# ECC_AGGR1_ECC_AGGR register map
Vendor: Texas Instruments
Registers are 32-bit, access not given, reset 0x0 unless marked. A register's access mark holds for its fields unless they carry their own. Offsets are as the file gives them; [hi:lo] are bit positions; {n}, {i} and the like mark numbered series.

## ECC_AGGR1_ECC_AGGR (part 6 of 6)
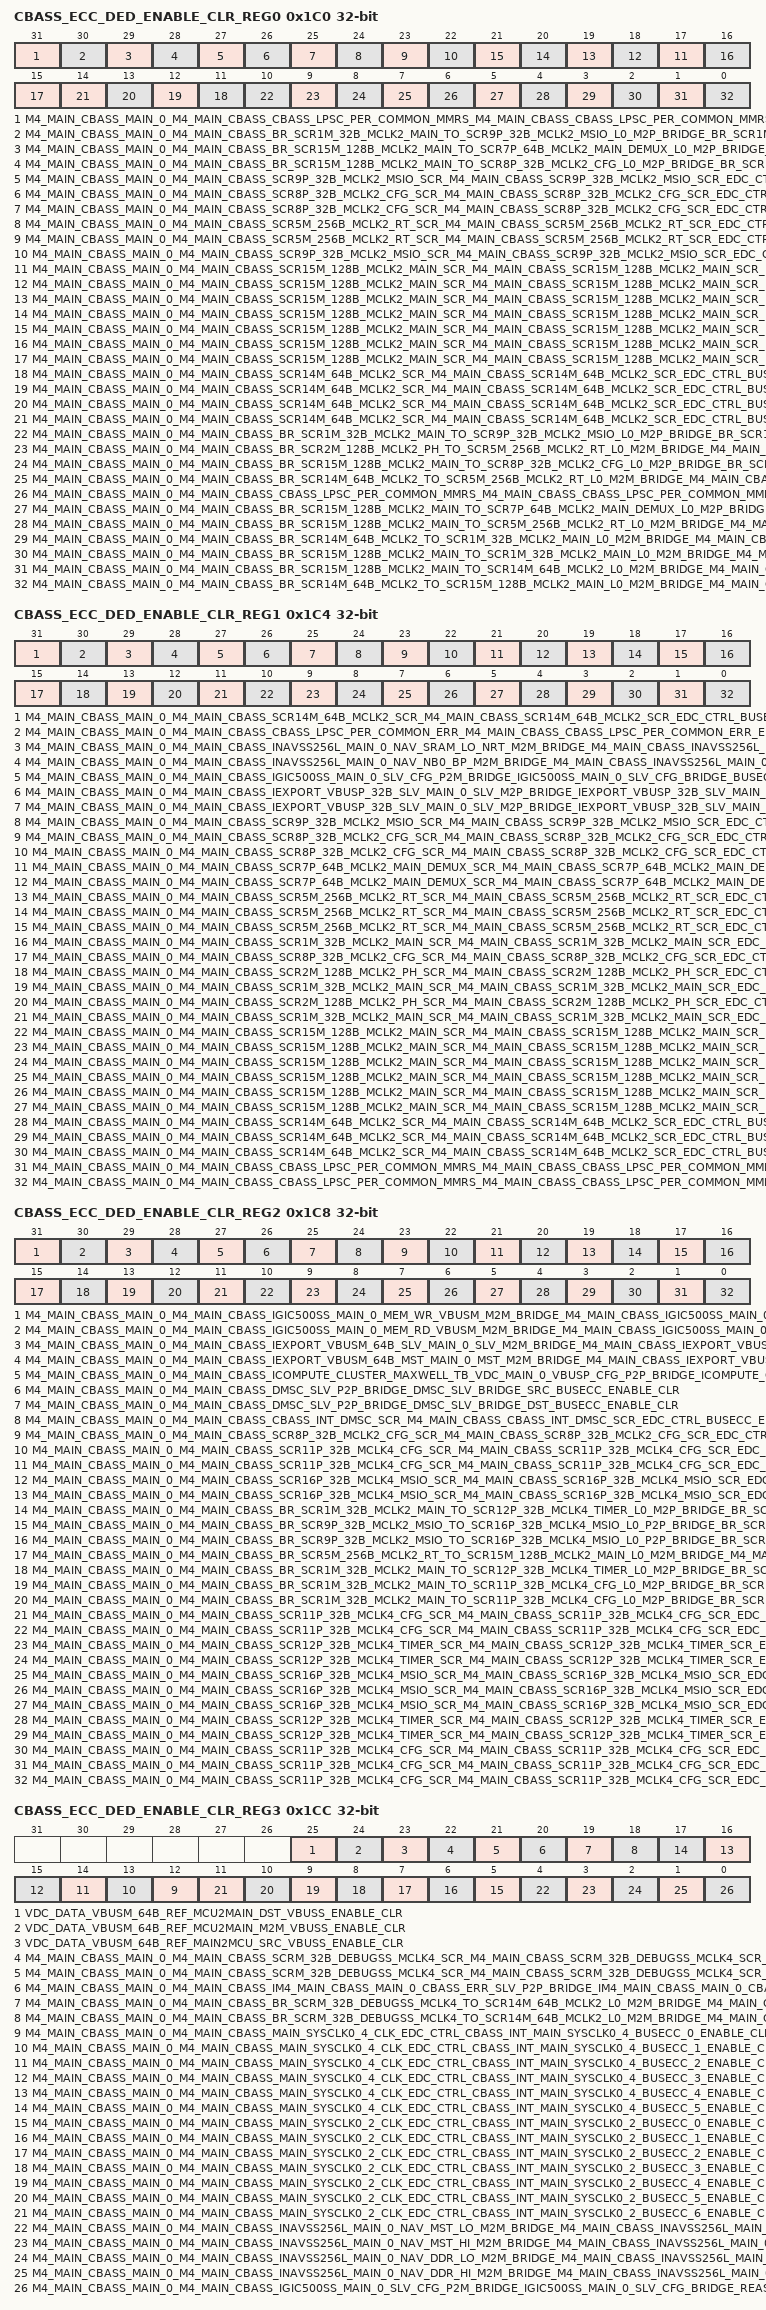
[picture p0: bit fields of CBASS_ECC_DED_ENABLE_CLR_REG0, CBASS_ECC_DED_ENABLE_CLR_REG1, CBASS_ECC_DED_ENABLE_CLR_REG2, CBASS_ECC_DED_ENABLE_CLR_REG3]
0x1C0 CBASS_ECC_DED_ENABLE_CLR_REG0 — Return to the . Interrupt Enable Clear Register 0
  [31] M4_MAIN_CBASS_MAIN_0_M4_MAIN_CBASS_CBASS_LPSC_PER_COMMON_MMRS_M4_MAIN_CBASS_CBASS_LPSC_PER_COMMON_MMRS_EDC_CTRL_BUSECC_1_ENABLE_CLR — Interrupt Enable Clear Register for m4_main_cbass_main_0_m4_main_cbass_cbass_LPSC_per_common_mmrs_m4_main_cbass_cbass_LPSC_per_common_mmrs_edc_ctrl_busecc_1__pend (access RW1C)
  [30] M4_MAIN_CBASS_MAIN_0_M4_MAIN_CBASS_BR_SCR1M_32B_MCLK2_MAIN_TO_SCR9P_32B_MCLK2_MSIO_L0_M2P_BRIDGE_BR_SCR1M_32B_MCLK2_MAIN_TO_SCR9P_32B_MCLK2_MSIO_L0_BRIDGE_DST_BUSECC_ENABLE_CLR — Interrupt Enable Clear Register for m4_main_cbass_main_0_m4_main_cbass_br_SCR1M_32b_MCLK2_main_to_SCR9P_32b_MCLK2_MSIO_l0_m2p_bridge_br_SCR1M_32b_MCLK2_main_to_SCR9P_32b_MCLK2_MSIO_l0_bridge_dst_busecc__pend (access RW1C)
  [29] M4_MAIN_CBASS_MAIN_0_M4_MAIN_CBASS_BR_SCR15M_128B_MCLK2_MAIN_TO_SCR7P_64B_MCLK2_MAIN_DEMUX_L0_M2P_BRIDGE_BR_SCR15M_128B_MCLK2_MAIN_TO_SCR7P_64B_MCLK2_MAIN_DEMUX_L0_BRIDGE_SRC_BUSECC_ENABLE_CLR — Interrupt Enable Clear Register for m4_main_cbass_main_0_m4_main_cbass_br_SCR15M_128b_MCLK2_main_to_SCR7P_64b_MCLK2_main_demux_l0_m2p_bridge_br_SCR15M_128b_MCLK2_main_to_SCR7P_64b_MCLK2_main_demux_l0_bridge_src_busecc__pend (access RW1C)
  [28] M4_MAIN_CBASS_MAIN_0_M4_MAIN_CBASS_BR_SCR15M_128B_MCLK2_MAIN_TO_SCR8P_32B_MCLK2_CFG_L0_M2P_BRIDGE_BR_SCR15M_128B_MCLK2_MAIN_TO_SCR8P_32B_MCLK2_CFG_L0_BRIDGE_DST_BUSECC_ENABLE_CLR — Interrupt Enable Clear Register for m4_main_cbass_main_0_m4_main_cbass_br_SCR15M_128b_MCLK2_main_to_SCR8P_32b_MCLK2_CFG_l0_m2p_bridge_br_SCR15M_128b_MCLK2_main_to_SCR8P_32b_MCLK2_CFG_l0_bridge_dst_busecc__pend (access RW1C)
  [27] M4_MAIN_CBASS_MAIN_0_M4_MAIN_CBASS_SCR9P_32B_MCLK2_MSIO_SCR_M4_MAIN_CBASS_SCR9P_32B_MCLK2_MSIO_SCR_EDC_CTRL_BUSECC_0_ENABLE_CLR — Interrupt Enable Clear Register for m4_main_cbass_main_0_m4_main_cbass_SCR9P_32b_MCLK2_MSIO_scr_m4_main_cbass_SCR9P_32b_MCLK2_MSIO_scr_edc_ctrl_busecc_0__pend (access RW1C)
  [26] M4_MAIN_CBASS_MAIN_0_M4_MAIN_CBASS_SCR8P_32B_MCLK2_CFG_SCR_M4_MAIN_CBASS_SCR8P_32B_MCLK2_CFG_SCR_EDC_CTRL_BUSECC_0_ENABLE_CLR — Interrupt Enable Clear Register for m4_main_cbass_main_0_m4_main_cbass_SCR8P_32b_MCLK2_CFG_scr_m4_main_cbass_SCR8P_32b_MCLK2_CFG_scr_edc_ctrl_busecc_0__pend (access RW1C)
  [25] M4_MAIN_CBASS_MAIN_0_M4_MAIN_CBASS_SCR8P_32B_MCLK2_CFG_SCR_M4_MAIN_CBASS_SCR8P_32B_MCLK2_CFG_SCR_EDC_CTRL_BUSECC_2_ENABLE_CLR — Interrupt Enable Clear Register for m4_main_cbass_main_0_m4_main_cbass_SCR8P_32b_MCLK2_CFG_scr_m4_main_cbass_SCR8P_32b_MCLK2_CFG_scr_edc_ctrl_busecc_2__pend (access RW1C)
  [24] M4_MAIN_CBASS_MAIN_0_M4_MAIN_CBASS_SCR5M_256B_MCLK2_RT_SCR_M4_MAIN_CBASS_SCR5M_256B_MCLK2_RT_SCR_EDC_CTRL_BUSECC_1_ENABLE_CLR — Interrupt Enable Clear Register for m4_main_cbass_main_0_m4_main_cbass_SCR5M_256b_MCLK2_RT_scr_m4_main_cbass_SCR5M_256b_MCLK2_RT_scr_edc_ctrl_busecc_1__pend (access RW1C)
  [23] M4_MAIN_CBASS_MAIN_0_M4_MAIN_CBASS_SCR5M_256B_MCLK2_RT_SCR_M4_MAIN_CBASS_SCR5M_256B_MCLK2_RT_SCR_EDC_CTRL_BUSECC_0_ENABLE_CLR — Interrupt Enable Clear Register for m4_main_cbass_main_0_m4_main_cbass_SCR5M_256b_MCLK2_RT_scr_m4_main_cbass_SCR5M_256b_MCLK2_RT_scr_edc_ctrl_busecc_0__pend (access RW1C)
  [22] M4_MAIN_CBASS_MAIN_0_M4_MAIN_CBASS_SCR9P_32B_MCLK2_MSIO_SCR_M4_MAIN_CBASS_SCR9P_32B_MCLK2_MSIO_SCR_EDC_CTRL_BUSECC_1_ENABLE_CLR — Interrupt Enable Clear Register for m4_main_cbass_main_0_m4_main_cbass_SCR9P_32b_MCLK2_MSIO_scr_m4_main_cbass_SCR9P_32b_MCLK2_MSIO_scr_edc_ctrl_busecc_1__pend (access RW1C)
  [n+15] M4_MAIN_CBASS_MAIN_0_M4_MAIN_CBASS_SCR15M_128B_MCLK2_MAIN_SCR_M4_MAIN_CBASS_SCR15M_128B_MCLK2_MAIN_SCR_EDC_CTRL_BUSECC_{n}_ENABLE_CLR (n=2..6) — Interrupt Enable Clear Register for m4_main_cbass_main_0_m4_main_cbass_SCR15M_128b_MCLK2_main_scr_m4_main_cbass_SCR15M_128b_MCLK2_main_scr_edc_ctrl_busecc_{n}__pend (access RW1C)
  [16] M4_MAIN_CBASS_MAIN_0_M4_MAIN_CBASS_SCR15M_128B_MCLK2_MAIN_SCR_M4_MAIN_CBASS_SCR15M_128B_MCLK2_MAIN_SCR_EDC_CTRL_BUSECC_0_ENABLE_CLR — Interrupt Enable Clear Register for m4_main_cbass_main_0_m4_main_cbass_SCR15M_128b_MCLK2_main_scr_m4_main_cbass_SCR15M_128b_MCLK2_main_scr_edc_ctrl_busecc_0__pend (access RW1C)
  [15] M4_MAIN_CBASS_MAIN_0_M4_MAIN_CBASS_SCR15M_128B_MCLK2_MAIN_SCR_M4_MAIN_CBASS_SCR15M_128B_MCLK2_MAIN_SCR_EDC_CTRL_BUSECC_1_ENABLE_CLR — Interrupt Enable Clear Register for m4_main_cbass_main_0_m4_main_cbass_SCR15M_128b_MCLK2_main_scr_m4_main_cbass_SCR15M_128b_MCLK2_main_scr_edc_ctrl_busecc_1__pend (access RW1C)
  [n+11] M4_MAIN_CBASS_MAIN_0_M4_MAIN_CBASS_SCR14M_64B_MCLK2_SCR_M4_MAIN_CBASS_SCR14M_64B_MCLK2_SCR_EDC_CTRL_BUSECC_{n}_ENABLE_CLR (n=0..3) — Interrupt Enable Clear Register for m4_main_cbass_main_0_m4_main_cbass_SCR14M_64b_MCLK2_scr_m4_main_cbass_SCR14M_64b_MCLK2_scr_edc_ctrl_busecc_{n}__pend (access RW1C)
  [10] M4_MAIN_CBASS_MAIN_0_M4_MAIN_CBASS_BR_SCR1M_32B_MCLK2_MAIN_TO_SCR9P_32B_MCLK2_MSIO_L0_M2P_BRIDGE_BR_SCR1M_32B_MCLK2_MAIN_TO_SCR9P_32B_MCLK2_MSIO_L0_BRIDGE_SRC_BUSECC_ENABLE_CLR — Interrupt Enable Clear Register for m4_main_cbass_main_0_m4_main_cbass_br_SCR1M_32b_MCLK2_main_to_SCR9P_32b_MCLK2_MSIO_l0_m2p_bridge_br_SCR1M_32b_MCLK2_main_to_SCR9P_32b_MCLK2_MSIO_l0_bridge_src_busecc__pend (access RW1C)
  [9] M4_MAIN_CBASS_MAIN_0_M4_MAIN_CBASS_BR_SCR2M_128B_MCLK2_PH_TO_SCR5M_256B_MCLK2_RT_L0_M2M_BRIDGE_M4_MAIN_CBASS_BR_SCR2M_128B_MCLK2_PH_TO_SCR5M_256B_MCLK2_RT_L0_M2M_BRIDGE_SRC_EDC_CTRL_BUSECC_ENABLE_CLR — Interrupt Enable Clear Register for m4_main_cbass_main_0_m4_main_cbass_br_SCR2M_128b_MCLK2_PH_to_SCR5M_256b_MCLK2_RT_l0_m2m_bridge_m4_main_cbass_br_SCR2M_128b_MCLK2_PH_to_SCR5M_256b_MCLK2_RT_l0_m2m_bridge_src_edc_ctrl_busecc__pend (access RW1C)
  [8] M4_MAIN_CBASS_MAIN_0_M4_MAIN_CBASS_BR_SCR15M_128B_MCLK2_MAIN_TO_SCR8P_32B_MCLK2_CFG_L0_M2P_BRIDGE_BR_SCR15M_128B_MCLK2_MAIN_TO_SCR8P_32B_MCLK2_CFG_L0_BRIDGE_SRC_BUSECC_ENABLE_CLR — Interrupt Enable Clear Register for m4_main_cbass_main_0_m4_main_cbass_br_SCR15M_128b_MCLK2_main_to_SCR8P_32b_MCLK2_CFG_l0_m2p_bridge_br_SCR15M_128b_MCLK2_main_to_SCR8P_32b_MCLK2_CFG_l0_bridge_src_busecc__pend (access RW1C)
  [7] M4_MAIN_CBASS_MAIN_0_M4_MAIN_CBASS_BR_SCR14M_64B_MCLK2_TO_SCR5M_256B_MCLK2_RT_L0_M2M_BRIDGE_M4_MAIN_CBASS_BR_SCR14M_64B_MCLK2_TO_SCR5M_256B_MCLK2_RT_L0_M2M_BRIDGE_SRC_EDC_CTRL_BUSECC_ENABLE_CLR — Interrupt Enable Clear Register for m4_main_cbass_main_0_m4_main_cbass_br_SCR14M_64b_MCLK2_to_SCR5M_256b_MCLK2_RT_l0_m2m_bridge_m4_main_cbass_br_SCR14M_64b_MCLK2_to_SCR5M_256b_MCLK2_RT_l0_m2m_bridge_src_edc_ctrl_busecc__pend (access RW1C)
  [6] M4_MAIN_CBASS_MAIN_0_M4_MAIN_CBASS_CBASS_LPSC_PER_COMMON_MMRS_M4_MAIN_CBASS_CBASS_LPSC_PER_COMMON_MMRS_EDC_CTRL_BUSECC_0_ENABLE_CLR — Interrupt Enable Clear Register for m4_main_cbass_main_0_m4_main_cbass_cbass_LPSC_per_common_mmrs_m4_main_cbass_cbass_LPSC_per_common_mmrs_edc_ctrl_busecc_0__pend (access RW1C)
  [5] M4_MAIN_CBASS_MAIN_0_M4_MAIN_CBASS_BR_SCR15M_128B_MCLK2_MAIN_TO_SCR7P_64B_MCLK2_MAIN_DEMUX_L0_M2P_BRIDGE_BR_SCR15M_128B_MCLK2_MAIN_TO_SCR7P_64B_MCLK2_MAIN_DEMUX_L0_BRIDGE_DST_BUSECC_ENABLE_CLR — Interrupt Enable Clear Register for m4_main_cbass_main_0_m4_main_cbass_br_SCR15M_128b_MCLK2_main_to_SCR7P_64b_MCLK2_main_demux_l0_m2p_bridge_br_SCR15M_128b_MCLK2_main_to_SCR7P_64b_MCLK2_main_demux_l0_bridge_dst_busecc__pend (access RW1C)
  [4] M4_MAIN_CBASS_MAIN_0_M4_MAIN_CBASS_BR_SCR15M_128B_MCLK2_MAIN_TO_SCR5M_256B_MCLK2_RT_L0_M2M_BRIDGE_M4_MAIN_CBASS_BR_SCR15M_128B_MCLK2_MAIN_TO_SCR5M_256B_MCLK2_RT_L0_M2M_BRIDGE_SRC_EDC_CTRL_BUSECC_ENABLE_CLR — Interrupt Enable Clear Register for m4_main_cbass_main_0_m4_main_cbass_br_SCR15M_128b_MCLK2_main_to_SCR5M_256b_MCLK2_RT_l0_m2m_bridge_m4_main_cbass_br_SCR15M_128b_MCLK2_main_to_SCR5M_256b_MCLK2_RT_l0_m2m_bridge_src_edc_ctrl_busecc__pend (access RW1C)
  [3] M4_MAIN_CBASS_MAIN_0_M4_MAIN_CBASS_BR_SCR14M_64B_MCLK2_TO_SCR1M_32B_MCLK2_MAIN_L0_M2M_BRIDGE_M4_MAIN_CBASS_BR_SCR14M_64B_MCLK2_TO_SCR1M_32B_MCLK2_MAIN_L0_M2M_BRIDGE_SRC_EDC_CTRL_BUSECC_ENABLE_CLR — Interrupt Enable Clear Register for m4_main_cbass_main_0_m4_main_cbass_br_SCR14M_64b_MCLK2_to_SCR1M_32b_MCLK2_main_l0_m2m_bridge_m4_main_cbass_br_SCR14M_64b_MCLK2_to_SCR1M_32b_MCLK2_main_l0_m2m_bridge_src_edc_ctrl_busecc__pend (access RW1C)
  [2] M4_MAIN_CBASS_MAIN_0_M4_MAIN_CBASS_BR_SCR15M_128B_MCLK2_MAIN_TO_SCR1M_32B_MCLK2_MAIN_L0_M2M_BRIDGE_M4_MAIN_CBASS_BR_SCR15M_128B_MCLK2_MAIN_TO_SCR1M_32B_MCLK2_MAIN_L0_M2M_BRIDGE_SRC_EDC_CTRL_BUSECC_ENABLE_CLR — Interrupt Enable Clear Register for m4_main_cbass_main_0_m4_main_cbass_br_SCR15M_128b_MCLK2_main_to_SCR1M_32b_MCLK2_main_l0_m2m_bridge_m4_main_cbass_br_SCR15M_128b_MCLK2_main_to_SCR1M_32b_MCLK2_main_l0_m2m_bridge_src_edc_ctrl_busecc__pend (access RW1C)
  [1] M4_MAIN_CBASS_MAIN_0_M4_MAIN_CBASS_BR_SCR15M_128B_MCLK2_MAIN_TO_SCR14M_64B_MCLK2_L0_M2M_BRIDGE_M4_MAIN_CBASS_BR_SCR15M_128B_MCLK2_MAIN_TO_SCR14M_64B_MCLK2_L0_M2M_BRIDGE_SRC_EDC_CTRL_BUSECC_ENABLE_CLR — Interrupt Enable Clear Register for m4_main_cbass_main_0_m4_main_cbass_br_SCR15M_128b_MCLK2_main_to_SCR14M_64b_MCLK2_l0_m2m_bridge_m4_main_cbass_br_SCR15M_128b_MCLK2_main_to_SCR14M_64b_MCLK2_l0_m2m_bridge_src_edc_ctrl_busecc__pend (access RW1C)
  [0] M4_MAIN_CBASS_MAIN_0_M4_MAIN_CBASS_BR_SCR14M_64B_MCLK2_TO_SCR15M_128B_MCLK2_MAIN_L0_M2M_BRIDGE_M4_MAIN_CBASS_BR_SCR14M_64B_MCLK2_TO_SCR15M_128B_MCLK2_MAIN_L0_M2M_BRIDGE_SRC_EDC_CTRL_BUSECC_ENABLE_CLR — Interrupt Enable Clear Register for m4_main_cbass_main_0_m4_main_cbass_br_SCR14M_64b_MCLK2_to_SCR15M_128b_MCLK2_main_l0_m2m_bridge_m4_main_cbass_br_SCR14M_64b_MCLK2_to_SCR15M_128b_MCLK2_main_l0_m2m_bridge_src_edc_ctrl_busecc__pend (access RW1C)
0x1C4 CBASS_ECC_DED_ENABLE_CLR_REG1 — Return to the . Interrupt Enable Clear Register 1
  [31] M4_MAIN_CBASS_MAIN_0_M4_MAIN_CBASS_SCR14M_64B_MCLK2_SCR_M4_MAIN_CBASS_SCR14M_64B_MCLK2_SCR_EDC_CTRL_BUSECC_4_ENABLE_CLR — Interrupt Enable Clear Register for m4_main_cbass_main_0_m4_main_cbass_SCR14M_64b_MCLK2_scr_m4_main_cbass_SCR14M_64b_MCLK2_scr_edc_ctrl_busecc_4__pend (access RW1C)
  [30] M4_MAIN_CBASS_MAIN_0_M4_MAIN_CBASS_CBASS_LPSC_PER_COMMON_ERR_M4_MAIN_CBASS_CBASS_LPSC_PER_COMMON_ERR_EDC_CTRL_BUSECC_ENABLE_CLR — Interrupt Enable Clear Register for m4_main_cbass_main_0_m4_main_cbass_cbass_LPSC_per_common_err_m4_main_cbass_cbass_LPSC_per_common_err_edc_ctrl_busecc__pend (access RW1C)
  [29] M4_MAIN_CBASS_MAIN_0_M4_MAIN_CBASS_INAVSS256L_MAIN_0_NAV_SRAM_LO_NRT_M2M_BRIDGE_M4_MAIN_CBASS_INAVSS256L_MAIN_0_NAV_SRAM_LO_NRT_M2M_BRIDGE_SRC_EDC_CTRL_BUSECC_ENABLE_CLR — Interrupt Enable Clear Register for m4_main_cbass_main_0_m4_main_cbass_Inavss256l_main_0_nav_sram_lo_nrt_m2m_bridge_m4_main_cbass_Inavss256l_main_0_nav_sram_lo_nrt_m2m_bridge_src_edc_ctrl_busecc__pend (access RW1C)
  [28] M4_MAIN_CBASS_MAIN_0_M4_MAIN_CBASS_INAVSS256L_MAIN_0_NAV_NB0_BP_M2M_BRIDGE_M4_MAIN_CBASS_INAVSS256L_MAIN_0_NAV_NB0_BP_M2M_BRIDGE_SRC_EDC_CTRL_BUSECC_ENABLE_CLR — Interrupt Enable Clear Register for m4_main_cbass_main_0_m4_main_cbass_Inavss256l_main_0_nav_nb0_bp_m2m_bridge_m4_main_cbass_Inavss256l_main_0_nav_nb0_bp_m2m_bridge_src_edc_ctrl_busecc__pend (access RW1C)
  [27] M4_MAIN_CBASS_MAIN_0_M4_MAIN_CBASS_IGIC500SS_MAIN_0_SLV_CFG_P2M_BRIDGE_IGIC500SS_MAIN_0_SLV_CFG_BRIDGE_BUSECC_ENABLE_CLR — Interrupt Enable Clear Register for m4_main_cbass_main_0_m4_main_cbass_Igic500ss_main_0_slv_cfg_p2m_bridge_Igic500ss_main_0_slv_cfg_bridge_busecc__pend (access RW1C)
  [26] M4_MAIN_CBASS_MAIN_0_M4_MAIN_CBASS_IEXPORT_VBUSP_32B_SLV_MAIN_0_SLV_M2P_BRIDGE_IEXPORT_VBUSP_32B_SLV_MAIN_0_SLV_BRIDGE_SRC_BUSECC_ENABLE_CLR — Interrupt Enable Clear Register for m4_main_cbass_main_0_m4_main_cbass_Iexport_vbusp_32b_slv_main_0_slv_m2p_bridge_Iexport_vbusp_32b_slv_main_0_slv_bridge_src_busecc__pend (access RW1C)
  [25] M4_MAIN_CBASS_MAIN_0_M4_MAIN_CBASS_IEXPORT_VBUSP_32B_SLV_MAIN_0_SLV_M2P_BRIDGE_IEXPORT_VBUSP_32B_SLV_MAIN_0_SLV_BRIDGE_DST_BUSECC_ENABLE_CLR — Interrupt Enable Clear Register for m4_main_cbass_main_0_m4_main_cbass_Iexport_vbusp_32b_slv_main_0_slv_m2p_bridge_Iexport_vbusp_32b_slv_main_0_slv_bridge_dst_busecc__pend (access RW1C)
  [24] M4_MAIN_CBASS_MAIN_0_M4_MAIN_CBASS_SCR9P_32B_MCLK2_MSIO_SCR_M4_MAIN_CBASS_SCR9P_32B_MCLK2_MSIO_SCR_EDC_CTRL_BUSECC_2_ENABLE_CLR — Interrupt Enable Clear Register for m4_main_cbass_main_0_m4_main_cbass_SCR9P_32b_MCLK2_MSIO_scr_m4_main_cbass_SCR9P_32b_MCLK2_MSIO_scr_edc_ctrl_busecc_2__pend (access RW1C)
  [23] M4_MAIN_CBASS_MAIN_0_M4_MAIN_CBASS_SCR8P_32B_MCLK2_CFG_SCR_M4_MAIN_CBASS_SCR8P_32B_MCLK2_CFG_SCR_EDC_CTRL_BUSECC_4_ENABLE_CLR — Interrupt Enable Clear Register for m4_main_cbass_main_0_m4_main_cbass_SCR8P_32b_MCLK2_CFG_scr_m4_main_cbass_SCR8P_32b_MCLK2_CFG_scr_edc_ctrl_busecc_4__pend (access RW1C)
  [22] M4_MAIN_CBASS_MAIN_0_M4_MAIN_CBASS_SCR8P_32B_MCLK2_CFG_SCR_M4_MAIN_CBASS_SCR8P_32B_MCLK2_CFG_SCR_EDC_CTRL_BUSECC_3_ENABLE_CLR — Interrupt Enable Clear Register for m4_main_cbass_main_0_m4_main_cbass_SCR8P_32b_MCLK2_CFG_scr_m4_main_cbass_SCR8P_32b_MCLK2_CFG_scr_edc_ctrl_busecc_3__pend (access RW1C)
  [21] M4_MAIN_CBASS_MAIN_0_M4_MAIN_CBASS_SCR7P_64B_MCLK2_MAIN_DEMUX_SCR_M4_MAIN_CBASS_SCR7P_64B_MCLK2_MAIN_DEMUX_SCR_EDC_CTRL_BUSECC_1_ENABLE_CLR — Interrupt Enable Clear Register for m4_main_cbass_main_0_m4_main_cbass_SCR7P_64b_MCLK2_main_demux_scr_m4_main_cbass_SCR7P_64b_MCLK2_main_demux_scr_edc_ctrl_busecc_1__pend (access RW1C)
  [20] M4_MAIN_CBASS_MAIN_0_M4_MAIN_CBASS_SCR7P_64B_MCLK2_MAIN_DEMUX_SCR_M4_MAIN_CBASS_SCR7P_64B_MCLK2_MAIN_DEMUX_SCR_EDC_CTRL_BUSECC_0_ENABLE_CLR — Interrupt Enable Clear Register for m4_main_cbass_main_0_m4_main_cbass_SCR7P_64b_MCLK2_main_demux_scr_m4_main_cbass_SCR7P_64b_MCLK2_main_demux_scr_edc_ctrl_busecc_0__pend (access RW1C)
  [19] M4_MAIN_CBASS_MAIN_0_M4_MAIN_CBASS_SCR5M_256B_MCLK2_RT_SCR_M4_MAIN_CBASS_SCR5M_256B_MCLK2_RT_SCR_EDC_CTRL_BUSECC_4_ENABLE_CLR — Interrupt Enable Clear Register for m4_main_cbass_main_0_m4_main_cbass_SCR5M_256b_MCLK2_RT_scr_m4_main_cbass_SCR5M_256b_MCLK2_RT_scr_edc_ctrl_busecc_4__pend (access RW1C)
  [18] M4_MAIN_CBASS_MAIN_0_M4_MAIN_CBASS_SCR5M_256B_MCLK2_RT_SCR_M4_MAIN_CBASS_SCR5M_256B_MCLK2_RT_SCR_EDC_CTRL_BUSECC_3_ENABLE_CLR — Interrupt Enable Clear Register for m4_main_cbass_main_0_m4_main_cbass_SCR5M_256b_MCLK2_RT_scr_m4_main_cbass_SCR5M_256b_MCLK2_RT_scr_edc_ctrl_busecc_3__pend (access RW1C)
  [17] M4_MAIN_CBASS_MAIN_0_M4_MAIN_CBASS_SCR5M_256B_MCLK2_RT_SCR_M4_MAIN_CBASS_SCR5M_256B_MCLK2_RT_SCR_EDC_CTRL_BUSECC_2_ENABLE_CLR — Interrupt Enable Clear Register for m4_main_cbass_main_0_m4_main_cbass_SCR5M_256b_MCLK2_RT_scr_m4_main_cbass_SCR5M_256b_MCLK2_RT_scr_edc_ctrl_busecc_2__pend (access RW1C)
  [16] M4_MAIN_CBASS_MAIN_0_M4_MAIN_CBASS_SCR1M_32B_MCLK2_MAIN_SCR_M4_MAIN_CBASS_SCR1M_32B_MCLK2_MAIN_SCR_EDC_CTRL_BUSECC_1_ENABLE_CLR — Interrupt Enable Clear Register for m4_main_cbass_main_0_m4_main_cbass_SCR1M_32b_MCLK2_main_scr_m4_main_cbass_SCR1M_32b_MCLK2_main_scr_edc_ctrl_busecc_1__pend (access RW1C)
  [15] M4_MAIN_CBASS_MAIN_0_M4_MAIN_CBASS_SCR8P_32B_MCLK2_CFG_SCR_M4_MAIN_CBASS_SCR8P_32B_MCLK2_CFG_SCR_EDC_CTRL_BUSECC_1_ENABLE_CLR — Interrupt Enable Clear Register for m4_main_cbass_main_0_m4_main_cbass_SCR8P_32b_MCLK2_CFG_scr_m4_main_cbass_SCR8P_32b_MCLK2_CFG_scr_edc_ctrl_busecc_1__pend (access RW1C)
  [14] M4_MAIN_CBASS_MAIN_0_M4_MAIN_CBASS_SCR2M_128B_MCLK2_PH_SCR_M4_MAIN_CBASS_SCR2M_128B_MCLK2_PH_SCR_EDC_CTRL_BUSECC_1_ENABLE_CLR — Interrupt Enable Clear Register for m4_main_cbass_main_0_m4_main_cbass_SCR2M_128b_MCLK2_PH_scr_m4_main_cbass_SCR2M_128b_MCLK2_PH_scr_edc_ctrl_busecc_1__pend (access RW1C)
  [13] M4_MAIN_CBASS_MAIN_0_M4_MAIN_CBASS_SCR1M_32B_MCLK2_MAIN_SCR_M4_MAIN_CBASS_SCR1M_32B_MCLK2_MAIN_SCR_EDC_CTRL_BUSECC_2_ENABLE_CLR — Interrupt Enable Clear Register for m4_main_cbass_main_0_m4_main_cbass_SCR1M_32b_MCLK2_main_scr_m4_main_cbass_SCR1M_32b_MCLK2_main_scr_edc_ctrl_busecc_2__pend (access RW1C)
  [12] M4_MAIN_CBASS_MAIN_0_M4_MAIN_CBASS_SCR2M_128B_MCLK2_PH_SCR_M4_MAIN_CBASS_SCR2M_128B_MCLK2_PH_SCR_EDC_CTRL_BUSECC_0_ENABLE_CLR — Interrupt Enable Clear Register for m4_main_cbass_main_0_m4_main_cbass_SCR2M_128b_MCLK2_PH_scr_m4_main_cbass_SCR2M_128b_MCLK2_PH_scr_edc_ctrl_busecc_0__pend (access RW1C)
  [11] M4_MAIN_CBASS_MAIN_0_M4_MAIN_CBASS_SCR1M_32B_MCLK2_MAIN_SCR_M4_MAIN_CBASS_SCR1M_32B_MCLK2_MAIN_SCR_EDC_CTRL_BUSECC_0_ENABLE_CLR — Interrupt Enable Clear Register for m4_main_cbass_main_0_m4_main_cbass_SCR1M_32b_MCLK2_main_scr_m4_main_cbass_SCR1M_32b_MCLK2_main_scr_edc_ctrl_busecc_0__pend (access RW1C)
  [10] M4_MAIN_CBASS_MAIN_0_M4_MAIN_CBASS_SCR15M_128B_MCLK2_MAIN_SCR_M4_MAIN_CBASS_SCR15M_128B_MCLK2_MAIN_SCR_EDC_CTRL_BUSECC_9_ENABLE_CLR — Interrupt Enable Clear Register for m4_main_cbass_main_0_m4_main_cbass_SCR15M_128b_MCLK2_main_scr_m4_main_cbass_SCR15M_128b_MCLK2_main_scr_edc_ctrl_busecc_9__pend (access RW1C)
  [9] M4_MAIN_CBASS_MAIN_0_M4_MAIN_CBASS_SCR15M_128B_MCLK2_MAIN_SCR_M4_MAIN_CBASS_SCR15M_128B_MCLK2_MAIN_SCR_EDC_CTRL_BUSECC_8_ENABLE_CLR — Interrupt Enable Clear Register for m4_main_cbass_main_0_m4_main_cbass_SCR15M_128b_MCLK2_main_scr_m4_main_cbass_SCR15M_128b_MCLK2_main_scr_edc_ctrl_busecc_8__pend (access RW1C)
  [8] M4_MAIN_CBASS_MAIN_0_M4_MAIN_CBASS_SCR15M_128B_MCLK2_MAIN_SCR_M4_MAIN_CBASS_SCR15M_128B_MCLK2_MAIN_SCR_EDC_CTRL_BUSECC_7_ENABLE_CLR — Interrupt Enable Clear Register for m4_main_cbass_main_0_m4_main_cbass_SCR15M_128b_MCLK2_main_scr_m4_main_cbass_SCR15M_128b_MCLK2_main_scr_edc_ctrl_busecc_7__pend (access RW1C)
  [7] M4_MAIN_CBASS_MAIN_0_M4_MAIN_CBASS_SCR15M_128B_MCLK2_MAIN_SCR_M4_MAIN_CBASS_SCR15M_128B_MCLK2_MAIN_SCR_EDC_CTRL_BUSECC_12_ENABLE_CLR — Interrupt Enable Clear Register for m4_main_cbass_main_0_m4_main_cbass_SCR15M_128b_MCLK2_main_scr_m4_main_cbass_SCR15M_128b_MCLK2_main_scr_edc_ctrl_busecc_12__pend (access RW1C)
  [6] M4_MAIN_CBASS_MAIN_0_M4_MAIN_CBASS_SCR15M_128B_MCLK2_MAIN_SCR_M4_MAIN_CBASS_SCR15M_128B_MCLK2_MAIN_SCR_EDC_CTRL_BUSECC_11_ENABLE_CLR — Interrupt Enable Clear Register for m4_main_cbass_main_0_m4_main_cbass_SCR15M_128b_MCLK2_main_scr_m4_main_cbass_SCR15M_128b_MCLK2_main_scr_edc_ctrl_busecc_11__pend (access RW1C)
  [5] M4_MAIN_CBASS_MAIN_0_M4_MAIN_CBASS_SCR15M_128B_MCLK2_MAIN_SCR_M4_MAIN_CBASS_SCR15M_128B_MCLK2_MAIN_SCR_EDC_CTRL_BUSECC_10_ENABLE_CLR — Interrupt Enable Clear Register for m4_main_cbass_main_0_m4_main_cbass_SCR15M_128b_MCLK2_main_scr_m4_main_cbass_SCR15M_128b_MCLK2_main_scr_edc_ctrl_busecc_10__pend (access RW1C)
  [4] M4_MAIN_CBASS_MAIN_0_M4_MAIN_CBASS_SCR14M_64B_MCLK2_SCR_M4_MAIN_CBASS_SCR14M_64B_MCLK2_SCR_EDC_CTRL_BUSECC_7_ENABLE_CLR — Interrupt Enable Clear Register for m4_main_cbass_main_0_m4_main_cbass_SCR14M_64b_MCLK2_scr_m4_main_cbass_SCR14M_64b_MCLK2_scr_edc_ctrl_busecc_7__pend (access RW1C)
  [3] M4_MAIN_CBASS_MAIN_0_M4_MAIN_CBASS_SCR14M_64B_MCLK2_SCR_M4_MAIN_CBASS_SCR14M_64B_MCLK2_SCR_EDC_CTRL_BUSECC_6_ENABLE_CLR — Interrupt Enable Clear Register for m4_main_cbass_main_0_m4_main_cbass_SCR14M_64b_MCLK2_scr_m4_main_cbass_SCR14M_64b_MCLK2_scr_edc_ctrl_busecc_6__pend (access RW1C)
  [2] M4_MAIN_CBASS_MAIN_0_M4_MAIN_CBASS_SCR14M_64B_MCLK2_SCR_M4_MAIN_CBASS_SCR14M_64B_MCLK2_SCR_EDC_CTRL_BUSECC_5_ENABLE_CLR — Interrupt Enable Clear Register for m4_main_cbass_main_0_m4_main_cbass_SCR14M_64b_MCLK2_scr_m4_main_cbass_SCR14M_64b_MCLK2_scr_edc_ctrl_busecc_5__pend (access RW1C)
  [1] M4_MAIN_CBASS_MAIN_0_M4_MAIN_CBASS_CBASS_LPSC_PER_COMMON_MMRS_M4_MAIN_CBASS_CBASS_LPSC_PER_COMMON_MMRS_EDC_CTRL_BUSECC_3_ENABLE_CLR — Interrupt Enable Clear Register for m4_main_cbass_main_0_m4_main_cbass_cbass_LPSC_per_common_mmrs_m4_main_cbass_cbass_LPSC_per_common_mmrs_edc_ctrl_busecc_3__pend (access RW1C)
  [0] M4_MAIN_CBASS_MAIN_0_M4_MAIN_CBASS_CBASS_LPSC_PER_COMMON_MMRS_M4_MAIN_CBASS_CBASS_LPSC_PER_COMMON_MMRS_EDC_CTRL_BUSECC_2_ENABLE_CLR — Interrupt Enable Clear Register for m4_main_cbass_main_0_m4_main_cbass_cbass_LPSC_per_common_mmrs_m4_main_cbass_cbass_LPSC_per_common_mmrs_edc_ctrl_busecc_2__pend (access RW1C)
0x1C8 CBASS_ECC_DED_ENABLE_CLR_REG2 — Return to the . Interrupt Enable Clear Register 2
  [31] M4_MAIN_CBASS_MAIN_0_M4_MAIN_CBASS_IGIC500SS_MAIN_0_MEM_WR_VBUSM_M2M_BRIDGE_M4_MAIN_CBASS_IGIC500SS_MAIN_0_MEM_WR_VBUSM_M2M_BRIDGE_SRC_EDC_CTRL_BUSECC_ENABLE_CLR — Interrupt Enable Clear Register for m4_main_cbass_main_0_m4_main_cbass_Igic500ss_main_0_mem_wr_vbusm_m2m_bridge_m4_main_cbass_Igic500ss_main_0_mem_wr_vbusm_m2m_bridge_src_edc_ctrl_busecc__pend (access RW1C)
  [30] M4_MAIN_CBASS_MAIN_0_M4_MAIN_CBASS_IGIC500SS_MAIN_0_MEM_RD_VBUSM_M2M_BRIDGE_M4_MAIN_CBASS_IGIC500SS_MAIN_0_MEM_RD_VBUSM_M2M_BRIDGE_SRC_EDC_CTRL_BUSECC_ENABLE_CLR — Interrupt Enable Clear Register for m4_main_cbass_main_0_m4_main_cbass_Igic500ss_main_0_mem_rd_vbusm_m2m_bridge_m4_main_cbass_Igic500ss_main_0_mem_rd_vbusm_m2m_bridge_src_edc_ctrl_busecc__pend (access RW1C)
  [29] M4_MAIN_CBASS_MAIN_0_M4_MAIN_CBASS_IEXPORT_VBUSM_64B_SLV_MAIN_0_SLV_M2M_BRIDGE_M4_MAIN_CBASS_IEXPORT_VBUSM_64B_SLV_MAIN_0_SLV_M2M_BRIDGE_SRC_EDC_CTRL_BUSECC_ENABLE_CLR — Interrupt Enable Clear Register for m4_main_cbass_main_0_m4_main_cbass_Iexport_vbusm_64b_slv_main_0_slv_m2m_bridge_m4_main_cbass_Iexport_vbusm_64b_slv_main_0_slv_m2m_bridge_src_edc_ctrl_busecc__pend (access RW1C)
  [28] M4_MAIN_CBASS_MAIN_0_M4_MAIN_CBASS_IEXPORT_VBUSM_64B_MST_MAIN_0_MST_M2M_BRIDGE_M4_MAIN_CBASS_IEXPORT_VBUSM_64B_MST_MAIN_0_MST_M2M_BRIDGE_SRC_EDC_CTRL_BUSECC_ENABLE_CLR — Interrupt Enable Clear Register for m4_main_cbass_main_0_m4_main_cbass_Iexport_vbusm_64b_mst_main_0_mst_m2m_bridge_m4_main_cbass_Iexport_vbusm_64b_mst_main_0_mst_m2m_bridge_src_edc_ctrl_busecc__pend (access RW1C)
  [27] M4_MAIN_CBASS_MAIN_0_M4_MAIN_CBASS_ICOMPUTE_CLUSTER_MAXWELL_TB_VDC_MAIN_0_VBUSP_CFG_P2P_BRIDGE_ICOMPUTE_CLUSTER_MAXWELL_TB_VDC_MAIN_0_VBUSP_CFG_BRIDGE_BUSECC_ENABLE_CLR — Interrupt Enable Clear Register for m4_main_cbass_main_0_m4_main_cbass_Icompute_cluster_maxwell_tb_vdc_main_0_vbusp_cfg_p2p_bridge_Icompute_cluster_maxwell_tb_vdc_main_0_vbusp_cfg_bridge_busecc__pend (access RW1C)
  [26] M4_MAIN_CBASS_MAIN_0_M4_MAIN_CBASS_DMSC_SLV_P2P_BRIDGE_DMSC_SLV_BRIDGE_SRC_BUSECC_ENABLE_CLR — Interrupt Enable Clear Register for m4_main_cbass_main_0_m4_main_cbass_dmsc_slv_p2p_bridge_dmsc_slv_bridge_src_busecc__pend (access RW1C)
  [25] M4_MAIN_CBASS_MAIN_0_M4_MAIN_CBASS_DMSC_SLV_P2P_BRIDGE_DMSC_SLV_BRIDGE_DST_BUSECC_ENABLE_CLR — Interrupt Enable Clear Register for m4_main_cbass_main_0_m4_main_cbass_dmsc_slv_p2p_bridge_dmsc_slv_bridge_dst_busecc__pend (access RW1C)
  [24] M4_MAIN_CBASS_MAIN_0_M4_MAIN_CBASS_CBASS_INT_DMSC_SCR_M4_MAIN_CBASS_CBASS_INT_DMSC_SCR_EDC_CTRL_BUSECC_ENABLE_CLR — Interrupt Enable Clear Register for m4_main_cbass_main_0_m4_main_cbass_cbass_int_dmsc_scr_m4_main_cbass_cbass_int_dmsc_scr_edc_ctrl_busecc__pend (access RW1C)
  [23] M4_MAIN_CBASS_MAIN_0_M4_MAIN_CBASS_SCR8P_32B_MCLK2_CFG_SCR_M4_MAIN_CBASS_SCR8P_32B_MCLK2_CFG_SCR_EDC_CTRL_BUSECC_5_ENABLE_CLR — Interrupt Enable Clear Register for m4_main_cbass_main_0_m4_main_cbass_SCR8P_32b_MCLK2_CFG_scr_m4_main_cbass_SCR8P_32b_MCLK2_CFG_scr_edc_ctrl_busecc_5__pend (access RW1C)
  [22] M4_MAIN_CBASS_MAIN_0_M4_MAIN_CBASS_SCR11P_32B_MCLK4_CFG_SCR_M4_MAIN_CBASS_SCR11P_32B_MCLK4_CFG_SCR_EDC_CTRL_BUSECC_2_ENABLE_CLR — Interrupt Enable Clear Register for m4_main_cbass_main_0_m4_main_cbass_SCR11P_32b_MCLK4_CFG_scr_m4_main_cbass_SCR11P_32b_MCLK4_CFG_scr_edc_ctrl_busecc_2__pend (access RW1C)
  [21] M4_MAIN_CBASS_MAIN_0_M4_MAIN_CBASS_SCR11P_32B_MCLK4_CFG_SCR_M4_MAIN_CBASS_SCR11P_32B_MCLK4_CFG_SCR_EDC_CTRL_BUSECC_0_ENABLE_CLR — Interrupt Enable Clear Register for m4_main_cbass_main_0_m4_main_cbass_SCR11P_32b_MCLK4_CFG_scr_m4_main_cbass_SCR11P_32b_MCLK4_CFG_scr_edc_ctrl_busecc_0__pend (access RW1C)
  [20] M4_MAIN_CBASS_MAIN_0_M4_MAIN_CBASS_SCR16P_32B_MCLK4_MSIO_SCR_M4_MAIN_CBASS_SCR16P_32B_MCLK4_MSIO_SCR_EDC_CTRL_BUSECC_4_ENABLE_CLR — Interrupt Enable Clear Register for m4_main_cbass_main_0_m4_main_cbass_SCR16P_32b_MCLK4_MSIO_scr_m4_main_cbass_SCR16P_32b_MCLK4_MSIO_scr_edc_ctrl_busecc_4__pend (access RW1C)
  [19] M4_MAIN_CBASS_MAIN_0_M4_MAIN_CBASS_SCR16P_32B_MCLK4_MSIO_SCR_M4_MAIN_CBASS_SCR16P_32B_MCLK4_MSIO_SCR_EDC_CTRL_BUSECC_3_ENABLE_CLR — Interrupt Enable Clear Register for m4_main_cbass_main_0_m4_main_cbass_SCR16P_32b_MCLK4_MSIO_scr_m4_main_cbass_SCR16P_32b_MCLK4_MSIO_scr_edc_ctrl_busecc_3__pend (access RW1C)
  [18] M4_MAIN_CBASS_MAIN_0_M4_MAIN_CBASS_BR_SCR1M_32B_MCLK2_MAIN_TO_SCR12P_32B_MCLK4_TIMER_L0_M2P_BRIDGE_BR_SCR1M_32B_MCLK2_MAIN_TO_SCR12P_32B_MCLK4_TIMER_L0_BRIDGE_SRC_BUSECC_ENABLE_CLR — Interrupt Enable Clear Register for m4_main_cbass_main_0_m4_main_cbass_br_SCR1M_32b_MCLK2_main_to_SCR12P_32b_MCLK4_timer_l0_m2p_bridge_br_SCR1M_32b_MCLK2_main_to_SCR12P_32b_MCLK4_timer_l0_bridge_src_busecc__pend (access RW1C)
  [17] M4_MAIN_CBASS_MAIN_0_M4_MAIN_CBASS_BR_SCR9P_32B_MCLK2_MSIO_TO_SCR16P_32B_MCLK4_MSIO_L0_P2P_BRIDGE_BR_SCR9P_32B_MCLK2_MSIO_TO_SCR16P_32B_MCLK4_MSIO_L0_BRIDGE_SRC_BUSECC_ENABLE_CLR — Interrupt Enable Clear Register for m4_main_cbass_main_0_m4_main_cbass_br_SCR9P_32b_MCLK2_MSIO_to_SCR16P_32b_MCLK4_MSIO_l0_p2p_bridge_br_SCR9P_32b_MCLK2_MSIO_to_SCR16P_32b_MCLK4_MSIO_l0_bridge_src_busecc__pend (access RW1C)
  [16] M4_MAIN_CBASS_MAIN_0_M4_MAIN_CBASS_BR_SCR9P_32B_MCLK2_MSIO_TO_SCR16P_32B_MCLK4_MSIO_L0_P2P_BRIDGE_BR_SCR9P_32B_MCLK2_MSIO_TO_SCR16P_32B_MCLK4_MSIO_L0_BRIDGE_DST_BUSECC_ENABLE_CLR — Interrupt Enable Clear Register for m4_main_cbass_main_0_m4_main_cbass_br_SCR9P_32b_MCLK2_MSIO_to_SCR16P_32b_MCLK4_MSIO_l0_p2p_bridge_br_SCR9P_32b_MCLK2_MSIO_to_SCR16P_32b_MCLK4_MSIO_l0_bridge_dst_busecc__pend (access RW1C)
  [15] M4_MAIN_CBASS_MAIN_0_M4_MAIN_CBASS_BR_SCR5M_256B_MCLK2_RT_TO_SCR15M_128B_MCLK2_MAIN_L0_M2M_BRIDGE_M4_MAIN_CBASS_BR_SCR5M_256B_MCLK2_RT_TO_SCR15M_128B_MCLK2_MAIN_L0_M2M_BRIDGE_SRC_EDC_CTRL_BUSECC_ENABLE_CLR — Interrupt Enable Clear Register for m4_main_cbass_main_0_m4_main_cbass_br_SCR5M_256b_MCLK2_RT_to_SCR15M_128b_MCLK2_main_l0_m2m_bridge_m4_main_cbass_br_SCR5M_256b_MCLK2_RT_to_SCR15M_128b_MCLK2_main_l0_m2m_bridge_src_edc_ctrl_busecc__pend (access RW1C)
  [14] M4_MAIN_CBASS_MAIN_0_M4_MAIN_CBASS_BR_SCR1M_32B_MCLK2_MAIN_TO_SCR12P_32B_MCLK4_TIMER_L0_M2P_BRIDGE_BR_SCR1M_32B_MCLK2_MAIN_TO_SCR12P_32B_MCLK4_TIMER_L0_BRIDGE_DST_BUSECC_ENABLE_CLR — Interrupt Enable Clear Register for m4_main_cbass_main_0_m4_main_cbass_br_SCR1M_32b_MCLK2_main_to_SCR12P_32b_MCLK4_timer_l0_m2p_bridge_br_SCR1M_32b_MCLK2_main_to_SCR12P_32b_MCLK4_timer_l0_bridge_dst_busecc__pend (access RW1C)
  [13] M4_MAIN_CBASS_MAIN_0_M4_MAIN_CBASS_BR_SCR1M_32B_MCLK2_MAIN_TO_SCR11P_32B_MCLK4_CFG_L0_M2P_BRIDGE_BR_SCR1M_32B_MCLK2_MAIN_TO_SCR11P_32B_MCLK4_CFG_L0_BRIDGE_SRC_BUSECC_ENABLE_CLR — Interrupt Enable Clear Register for m4_main_cbass_main_0_m4_main_cbass_br_SCR1M_32b_MCLK2_main_to_SCR11P_32b_MCLK4_CFG_l0_m2p_bridge_br_SCR1M_32b_MCLK2_main_to_SCR11P_32b_MCLK4_CFG_l0_bridge_src_busecc__pend (access RW1C)
  [12] M4_MAIN_CBASS_MAIN_0_M4_MAIN_CBASS_BR_SCR1M_32B_MCLK2_MAIN_TO_SCR11P_32B_MCLK4_CFG_L0_M2P_BRIDGE_BR_SCR1M_32B_MCLK2_MAIN_TO_SCR11P_32B_MCLK4_CFG_L0_BRIDGE_DST_BUSECC_ENABLE_CLR — Interrupt Enable Clear Register for m4_main_cbass_main_0_m4_main_cbass_br_SCR1M_32b_MCLK2_main_to_SCR11P_32b_MCLK4_CFG_l0_m2p_bridge_br_SCR1M_32b_MCLK2_main_to_SCR11P_32b_MCLK4_CFG_l0_bridge_dst_busecc__pend (access RW1C)
  [11] M4_MAIN_CBASS_MAIN_0_M4_MAIN_CBASS_SCR11P_32B_MCLK4_CFG_SCR_M4_MAIN_CBASS_SCR11P_32B_MCLK4_CFG_SCR_EDC_CTRL_BUSECC_1_ENABLE_CLR — Interrupt Enable Clear Register for m4_main_cbass_main_0_m4_main_cbass_SCR11P_32b_MCLK4_CFG_scr_m4_main_cbass_SCR11P_32b_MCLK4_CFG_scr_edc_ctrl_busecc_1__pend (access RW1C)
  [10] M4_MAIN_CBASS_MAIN_0_M4_MAIN_CBASS_SCR11P_32B_MCLK4_CFG_SCR_M4_MAIN_CBASS_SCR11P_32B_MCLK4_CFG_SCR_EDC_CTRL_BUSECC_3_ENABLE_CLR — Interrupt Enable Clear Register for m4_main_cbass_main_0_m4_main_cbass_SCR11P_32b_MCLK4_CFG_scr_m4_main_cbass_SCR11P_32b_MCLK4_CFG_scr_edc_ctrl_busecc_3__pend (access RW1C)
  [9] M4_MAIN_CBASS_MAIN_0_M4_MAIN_CBASS_SCR12P_32B_MCLK4_TIMER_SCR_M4_MAIN_CBASS_SCR12P_32B_MCLK4_TIMER_SCR_EDC_CTRL_BUSECC_0_ENABLE_CLR — Interrupt Enable Clear Register for m4_main_cbass_main_0_m4_main_cbass_SCR12P_32b_MCLK4_timer_scr_m4_main_cbass_SCR12P_32b_MCLK4_timer_scr_edc_ctrl_busecc_0__pend (access RW1C)
  [8] M4_MAIN_CBASS_MAIN_0_M4_MAIN_CBASS_SCR12P_32B_MCLK4_TIMER_SCR_M4_MAIN_CBASS_SCR12P_32B_MCLK4_TIMER_SCR_EDC_CTRL_BUSECC_1_ENABLE_CLR — Interrupt Enable Clear Register for m4_main_cbass_main_0_m4_main_cbass_SCR12P_32b_MCLK4_timer_scr_m4_main_cbass_SCR12P_32b_MCLK4_timer_scr_edc_ctrl_busecc_1__pend (access RW1C)
  [7] M4_MAIN_CBASS_MAIN_0_M4_MAIN_CBASS_SCR16P_32B_MCLK4_MSIO_SCR_M4_MAIN_CBASS_SCR16P_32B_MCLK4_MSIO_SCR_EDC_CTRL_BUSECC_0_ENABLE_CLR — Interrupt Enable Clear Register for m4_main_cbass_main_0_m4_main_cbass_SCR16P_32b_MCLK4_MSIO_scr_m4_main_cbass_SCR16P_32b_MCLK4_MSIO_scr_edc_ctrl_busecc_0__pend (access RW1C)
  [6] M4_MAIN_CBASS_MAIN_0_M4_MAIN_CBASS_SCR16P_32B_MCLK4_MSIO_SCR_M4_MAIN_CBASS_SCR16P_32B_MCLK4_MSIO_SCR_EDC_CTRL_BUSECC_1_ENABLE_CLR — Interrupt Enable Clear Register for m4_main_cbass_main_0_m4_main_cbass_SCR16P_32b_MCLK4_MSIO_scr_m4_main_cbass_SCR16P_32b_MCLK4_MSIO_scr_edc_ctrl_busecc_1__pend (access RW1C)
  [5] M4_MAIN_CBASS_MAIN_0_M4_MAIN_CBASS_SCR16P_32B_MCLK4_MSIO_SCR_M4_MAIN_CBASS_SCR16P_32B_MCLK4_MSIO_SCR_EDC_CTRL_BUSECC_2_ENABLE_CLR — Interrupt Enable Clear Register for m4_main_cbass_main_0_m4_main_cbass_SCR16P_32b_MCLK4_MSIO_scr_m4_main_cbass_SCR16P_32b_MCLK4_MSIO_scr_edc_ctrl_busecc_2__pend (access RW1C)
  [4] M4_MAIN_CBASS_MAIN_0_M4_MAIN_CBASS_SCR12P_32B_MCLK4_TIMER_SCR_M4_MAIN_CBASS_SCR12P_32B_MCLK4_TIMER_SCR_EDC_CTRL_BUSECC_3_ENABLE_CLR — Interrupt Enable Clear Register for m4_main_cbass_main_0_m4_main_cbass_SCR12P_32b_MCLK4_timer_scr_m4_main_cbass_SCR12P_32b_MCLK4_timer_scr_edc_ctrl_busecc_3__pend (access RW1C)
  [3] M4_MAIN_CBASS_MAIN_0_M4_MAIN_CBASS_SCR12P_32B_MCLK4_TIMER_SCR_M4_MAIN_CBASS_SCR12P_32B_MCLK4_TIMER_SCR_EDC_CTRL_BUSECC_2_ENABLE_CLR — Interrupt Enable Clear Register for m4_main_cbass_main_0_m4_main_cbass_SCR12P_32b_MCLK4_timer_scr_m4_main_cbass_SCR12P_32b_MCLK4_timer_scr_edc_ctrl_busecc_2__pend (access RW1C)
  [2] M4_MAIN_CBASS_MAIN_0_M4_MAIN_CBASS_SCR11P_32B_MCLK4_CFG_SCR_M4_MAIN_CBASS_SCR11P_32B_MCLK4_CFG_SCR_EDC_CTRL_BUSECC_6_ENABLE_CLR — Interrupt Enable Clear Register for m4_main_cbass_main_0_m4_main_cbass_SCR11P_32b_MCLK4_CFG_scr_m4_main_cbass_SCR11P_32b_MCLK4_CFG_scr_edc_ctrl_busecc_6__pend (access RW1C)
  [1] M4_MAIN_CBASS_MAIN_0_M4_MAIN_CBASS_SCR11P_32B_MCLK4_CFG_SCR_M4_MAIN_CBASS_SCR11P_32B_MCLK4_CFG_SCR_EDC_CTRL_BUSECC_5_ENABLE_CLR — Interrupt Enable Clear Register for m4_main_cbass_main_0_m4_main_cbass_SCR11P_32b_MCLK4_CFG_scr_m4_main_cbass_SCR11P_32b_MCLK4_CFG_scr_edc_ctrl_busecc_5__pend (access RW1C)
  [0] M4_MAIN_CBASS_MAIN_0_M4_MAIN_CBASS_SCR11P_32B_MCLK4_CFG_SCR_M4_MAIN_CBASS_SCR11P_32B_MCLK4_CFG_SCR_EDC_CTRL_BUSECC_4_ENABLE_CLR — Interrupt Enable Clear Register for m4_main_cbass_main_0_m4_main_cbass_SCR11P_32b_MCLK4_CFG_scr_m4_main_cbass_SCR11P_32b_MCLK4_CFG_scr_edc_ctrl_busecc_4__pend (access RW1C)
0x1CC CBASS_ECC_DED_ENABLE_CLR_REG3 — Return to the . Interrupt Enable Clear Register 3
  [25] VDC_DATA_VBUSM_64B_REF_MCU2MAIN_DST_VBUSS_ENABLE_CLR — Interrupt Enable Clear Register for vdc_data_vbusm_64b_ref_mcu2main_dst_vbuss__pend (access RW1C)
  [24] VDC_DATA_VBUSM_64B_REF_MCU2MAIN_M2M_VBUSS_ENABLE_CLR — Interrupt Enable Clear Register for vdc_data_vbusm_64b_ref_mcu2main_m2m_vbuss__pend (access RW1C)
  [23] VDC_DATA_VBUSM_64B_REF_MAIN2MCU_SRC_VBUSS_ENABLE_CLR — Interrupt Enable Clear Register for vdc_data_vbusm_64b_ref_main2mcu_src_vbuss__pend (access RW1C)
  [22] M4_MAIN_CBASS_MAIN_0_M4_MAIN_CBASS_SCRM_32B_DEBUGSS_MCLK4_SCR_M4_MAIN_CBASS_SCRM_32B_DEBUGSS_MCLK4_SCR_EDC_CTRL_BUSECC_1_ENABLE_CLR — Interrupt Enable Clear Register for m4_main_cbass_main_0_m4_main_cbass_SCRM_32b_debugss_MCLK4_scr_m4_main_cbass_SCRM_32b_debugss_MCLK4_scr_edc_ctrl_busecc_1__pend (access RW1C)
  [21] M4_MAIN_CBASS_MAIN_0_M4_MAIN_CBASS_SCRM_32B_DEBUGSS_MCLK4_SCR_M4_MAIN_CBASS_SCRM_32B_DEBUGSS_MCLK4_SCR_EDC_CTRL_BUSECC_0_ENABLE_CLR — Interrupt Enable Clear Register for m4_main_cbass_main_0_m4_main_cbass_SCRM_32b_debugss_MCLK4_scr_m4_main_cbass_SCRM_32b_debugss_MCLK4_scr_edc_ctrl_busecc_0__pend (access RW1C)
  [20] M4_MAIN_CBASS_MAIN_0_M4_MAIN_CBASS_IM4_MAIN_CBASS_MAIN_0_CBASS_ERR_SLV_P2P_BRIDGE_IM4_MAIN_CBASS_MAIN_0_CBASS_ERR_SLV_BRIDGE_BUSECC_ENABLE_CLR — Interrupt Enable Clear Register for m4_main_cbass_main_0_m4_main_cbass_Im4_main_cbass_main_0_cbass_err_slv_p2p_bridge_Im4_main_cbass_main_0_cbass_err_slv_bridge_busecc__pend (access RW1C)
  [19] M4_MAIN_CBASS_MAIN_0_M4_MAIN_CBASS_BR_SCRM_32B_DEBUGSS_MCLK4_TO_SCR14M_64B_MCLK2_L0_M2M_BRIDGE_M4_MAIN_CBASS_BR_SCRM_32B_DEBUGSS_MCLK4_TO_SCR14M_64B_MCLK2_L0_M2M_BRIDGE_SRC_EDC_CTRL_BUSECC_ENABLE_CLR — Interrupt Enable Clear Register for m4_main_cbass_main_0_m4_main_cbass_br_SCRM_32b_debugss_MCLK4_to_SCR14M_64b_MCLK2_l0_m2m_bridge_m4_main_cbass_br_SCRM_32b_debugss_MCLK4_to_SCR14M_64b_MCLK2_l0_m2m_bridge_src_edc_ctrl_busecc__pend (access RW1C)
  [18] M4_MAIN_CBASS_MAIN_0_M4_MAIN_CBASS_BR_SCRM_32B_DEBUGSS_MCLK4_TO_SCR14M_64B_MCLK2_L0_M2M_BRIDGE_M4_MAIN_CBASS_BR_SCRM_32B_DEBUGSS_MCLK4_TO_SCR14M_64B_MCLK2_L0_M2M_BRIDGE_DST_EDC_CTRL_BUSECC_ENABLE_CLR — Interrupt Enable Clear Register for m4_main_cbass_main_0_m4_main_cbass_br_SCRM_32b_debugss_MCLK4_to_SCR14M_64b_MCLK2_l0_m2m_bridge_m4_main_cbass_br_SCRM_32b_debugss_MCLK4_to_SCR14M_64b_MCLK2_l0_m2m_bridge_dst_edc_ctrl_busecc__pend (access RW1C)
  [n+12] M4_MAIN_CBASS_MAIN_0_M4_MAIN_CBASS_MAIN_SYSCLK0_4_CLK_EDC_CTRL_CBASS_INT_MAIN_SYSCLK0_4_BUSECC_{n}_ENABLE_CLR (n=0..5) — Interrupt Enable Clear Register for m4_main_cbass_main_0_m4_main_cbass_main_sysclk0_4_clk_edc_ctrl_cbass_int_main_sysclk0_4_busecc_{n}__pend (access RW1C)
  [n+5] M4_MAIN_CBASS_MAIN_0_M4_MAIN_CBASS_MAIN_SYSCLK0_2_CLK_EDC_CTRL_CBASS_INT_MAIN_SYSCLK0_2_BUSECC_{n}_ENABLE_CLR (n=0..6) — Interrupt Enable Clear Register for m4_main_cbass_main_0_m4_main_cbass_main_sysclk0_2_clk_edc_ctrl_cbass_int_main_sysclk0_2_busecc_{n}__pend (access RW1C)
  [4] M4_MAIN_CBASS_MAIN_0_M4_MAIN_CBASS_INAVSS256L_MAIN_0_NAV_MST_LO_M2M_BRIDGE_M4_MAIN_CBASS_INAVSS256L_MAIN_0_NAV_MST_LO_M2M_BRIDGE_SRC_EDC_CTRL_BUSECC_ENABLE_CLR — Interrupt Enable Clear Register for m4_main_cbass_main_0_m4_main_cbass_Inavss256l_main_0_nav_mst_lo_m2m_bridge_m4_main_cbass_Inavss256l_main_0_nav_mst_lo_m2m_bridge_src_edc_ctrl_busecc__pend (access RW1C)
  [3] M4_MAIN_CBASS_MAIN_0_M4_MAIN_CBASS_INAVSS256L_MAIN_0_NAV_MST_HI_M2M_BRIDGE_M4_MAIN_CBASS_INAVSS256L_MAIN_0_NAV_MST_HI_M2M_BRIDGE_SRC_EDC_CTRL_BUSECC_ENABLE_CLR — Interrupt Enable Clear Register for m4_main_cbass_main_0_m4_main_cbass_Inavss256l_main_0_nav_mst_hi_m2m_bridge_m4_main_cbass_Inavss256l_main_0_nav_mst_hi_m2m_bridge_src_edc_ctrl_busecc__pend (access RW1C)
  [2] M4_MAIN_CBASS_MAIN_0_M4_MAIN_CBASS_INAVSS256L_MAIN_0_NAV_DDR_LO_M2M_BRIDGE_M4_MAIN_CBASS_INAVSS256L_MAIN_0_NAV_DDR_LO_M2M_BRIDGE_SRC_EDC_CTRL_BUSECC_ENABLE_CLR — Interrupt Enable Clear Register for m4_main_cbass_main_0_m4_main_cbass_Inavss256l_main_0_nav_ddr_lo_m2m_bridge_m4_main_cbass_Inavss256l_main_0_nav_ddr_lo_m2m_bridge_src_edc_ctrl_busecc__pend (access RW1C)
  [1] M4_MAIN_CBASS_MAIN_0_M4_MAIN_CBASS_INAVSS256L_MAIN_0_NAV_DDR_HI_M2M_BRIDGE_M4_MAIN_CBASS_INAVSS256L_MAIN_0_NAV_DDR_HI_M2M_BRIDGE_SRC_EDC_CTRL_BUSECC_ENABLE_CLR — Interrupt Enable Clear Register for m4_main_cbass_main_0_m4_main_cbass_Inavss256l_main_0_nav_ddr_hi_m2m_bridge_m4_main_cbass_Inavss256l_main_0_nav_ddr_hi_m2m_bridge_src_edc_ctrl_busecc__pend (access RW1C)
  [0] M4_MAIN_CBASS_MAIN_0_M4_MAIN_CBASS_IGIC500SS_MAIN_0_SLV_CFG_P2M_BRIDGE_IGIC500SS_MAIN_0_SLV_CFG_BRIDGE_REASSEMBLY_BUSECC_ENABLE_CLR — Interrupt Enable Clear Register for m4_main_cbass_main_0_m4_main_cbass_Igic500ss_main_0_slv_cfg_p2m_bridge_Igic500ss_main_0_slv_cfg_bridge_reassembly_busecc__pend (access RW1C)
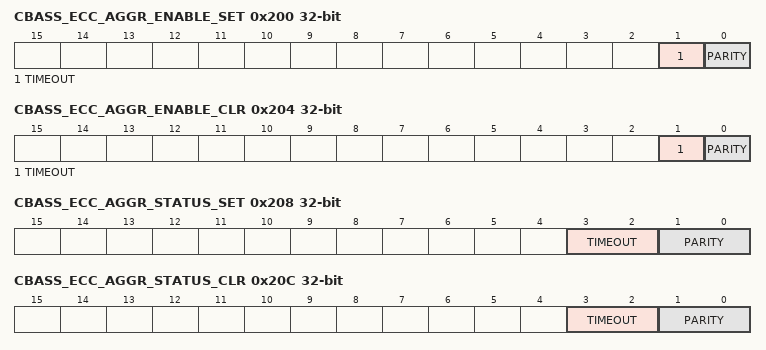
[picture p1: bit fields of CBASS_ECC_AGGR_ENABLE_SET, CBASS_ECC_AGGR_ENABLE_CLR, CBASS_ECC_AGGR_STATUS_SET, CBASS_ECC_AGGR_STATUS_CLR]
0x200 CBASS_ECC_AGGR_ENABLE_SET — Return to the . AGGR interrupt enable set Register
  [1] TIMEOUT — interrupt enable set for svbus timeout errors (access RW1S)
  [0] PARITY — interrupt enable set for parity errors (access RW1S)
0x204 CBASS_ECC_AGGR_ENABLE_CLR — Return to the . AGGR interrupt enable clear Register
  [1] TIMEOUT — interrupt enable clear for svbus timeout errors (access RW1C)
  [0] PARITY — interrupt enable clear for parity errors (access RW1C)
0x208 CBASS_ECC_AGGR_STATUS_SET rw — Return to the . AGGR interrupt status set Register
  [3:2] TIMEOUT — interrupt status set for svbus timeout errors
  [1:0] PARITY — interrupt status set for parity errors
0x20C CBASS_ECC_AGGR_STATUS_CLR rw — Return to the . AGGR interrupt status clear Register
  [3:2] TIMEOUT — interrupt status clear for svbus timeout errors
  [1:0] PARITY — interrupt status clear for parity errors
